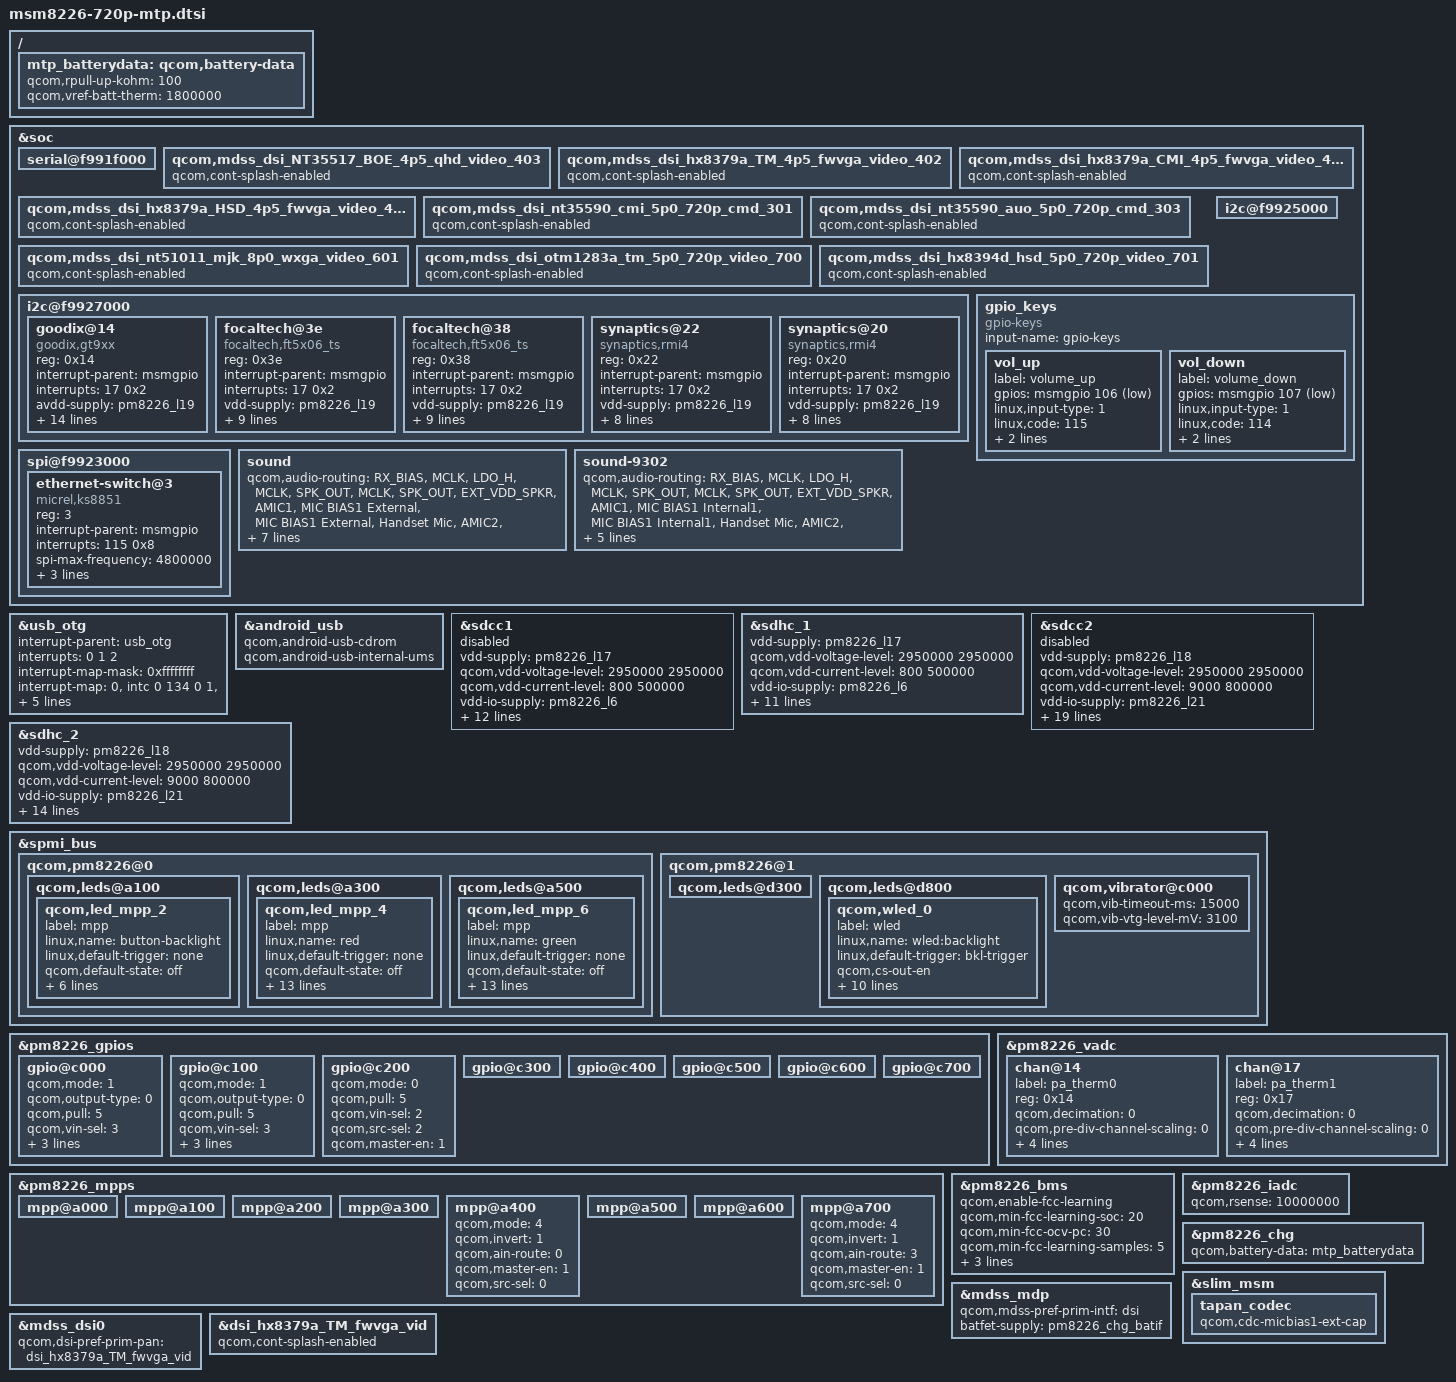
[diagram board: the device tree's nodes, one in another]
/* Copyright (c) 2013, The Linux Foundation. All rights reserved.
 *
 * This program is free software; you can redistribute it and/or modify
 * it under the terms of the GNU General Public License version 2 and
 * only version 2 as published by the Free Software Foundation.
 *
 * This program is distributed in the hope that it will be useful,
 * but WITHOUT ANY WARRANTY; without even the implied warranty of
 * MERCHANTABILITY or FITNESS FOR A PARTICULAR PURPOSE.  See the
 * GNU General Public License for more details.
 */

/include/ "msm8226-camera-sensor-mtp.dtsi"
/include/ "dsi-panel-HX8379A-CMI-IPS-4p5-FWVGA-video-zte-400.dtsi"
/include/ "dsi-panel-HX8379A-HSD-TN-4p5-FWVGA-video-zte-401.dtsi"
/include/ "dsi-panel-HX8379A-TM-TM-4p5-FWVGA-video-zte-402.dtsi"
/include/ "dsi-panel-NT35517-BOE-BOE-4p5-QHD-video-zte-403.dtsi"
/include/ "dsi-panel-nt35590-cmi-5p0-720p-cmd-zte-301.dtsi"
/include/ "dsi-panel-nt35590-auo-5p0-720p-cmd-zte-303.dtsi"
/include/ "dsi-panel-nt51011-mjk-8p0-WXGA-video-zte-601.dtsi"
/include/ "dsi-panel-otm1283a-tm-5p0-720p-video-zte-700.dtsi"
/include/ "dsi-panel-hx8394d-hsd-5p0-720p-video-zte-701.dtsi"
/include/ "dsi-panel-zte-hsd-nt35512-4p0-wvga-video.dtsi"

&soc {
	serial@f991f000 {
		status = "ok";
	};
	qcom,mdss_dsi_NT35517_BOE_4p5_qhd_video_403 {
		status = "ok";
		qcom,cont-splash-enabled;
	};
	qcom,mdss_dsi_hx8379a_TM_4p5_fwvga_video_402 {
		status = "ok";
		qcom,cont-splash-enabled;
	};

	qcom,mdss_dsi_hx8379a_CMI_4p5_fwvga_video_400 {
		status = "ok";
		qcom,cont-splash-enabled;
	};
	qcom,mdss_dsi_hx8379a_HSD_4p5_fwvga_video_401 {
		status = "ok";
		qcom,cont-splash-enabled;
	};
	qcom,mdss_dsi_nt35590_cmi_5p0_720p_cmd_301 {
		status = "ok";
		qcom,cont-splash-enabled;
	};
	qcom,mdss_dsi_nt35590_auo_5p0_720p_cmd_303 {
		status = "ok";
		qcom,cont-splash-enabled;
	};
	qcom,mdss_dsi_nt51011_mjk_8p0_wxga_video_601{
		status = "ok";
		qcom,cont-splash-enabled;
	};
	qcom,mdss_dsi_otm1283a_tm_5p0_720p_video_700{
		status = "ok";
		qcom,cont-splash-enabled;
	};
	qcom,mdss_dsi_hx8394d_hsd_5p0_720p_video_701{
		status = "ok";
		qcom,cont-splash-enabled;
	};
	i2c@f9927000 { /* BLSP1 QUP5 */
	goodix@14 {
			compatible = "goodix,gt9xx";
			reg = <0x14>;
			interrupt-parent = <&msmgpio>;
			interrupts = <17 0x2>;
            avdd-supply = <&pm8226_l19>;
			vdd-supply = <&pm8226_l19>;
			vcc_i2c-supply = <&pm8226_lvs1>;
			reset-gpios = <&msmgpio 16 0x00>;
			interrupt-gpios = <&msmgpio 17 0x00>;
			goodix,panel-coords = <0 0 480 900>;
			goodix,display-coords = <0 0 480 854>;
			goodix,button-map= <158 102 139>;
			regulator-min-microvolt = <2800000>;
			regulator-max-microvolt = <2800000>;
			goodix,family-id = <0x0>;
			goodix,no-force-update;
			goodix,i2c-pull-up;
			goodix,cfg-data = [
41 00 10 00 10 05 05 00 01 0F
28 0F 50 37 03 05 00 00 00 00
00 00 00 00 00 00 00 88 28 0A
40 42 7C 06 00 00 00 9B 03 25
00 00 00 00 00 00 64 32 00 00
00 28 6E 94 C2 02 05 00 00 04
B6 2C 00 96 36 00 7C 42 00 66
51 00 55 63 00 55 00 00 00 00
00 00 00 00 00 00 00 00 00 00
00 00 00 00 00 00 00 00 00 00
00 00 00 00 00 00 00 00 00 00
00 00 08 0A 0C 0E 10 12 14 16
18 1A 00 00 00 00 00 00 00 00
00 00 00 00 00 00 00 00 00 00
00 00 00 02 04 05 06 08 0A 0C
1D 1E 1F 20 22 24 28 29 FF 00
00 00 00 00 00 00 00 00 00 00
00 00 00 00 00 00 00 00 00 00
00 00 00 00 64 5A 50 50 50 50
46 46 5A 46 46 32 1E 00 00 00
00 00 00 00 00 00 00 00 00 00
00 00 00 00 00 00 00 00 00 00
00 00 00 00 00 00 D8 01
		];
		};
		focaltech@3e{
			compatible = "focaltech,ft5x06_ts";
			reg = <0x3e>;
			interrupt-parent = <&msmgpio>;
			interrupts = <17 0x2>;
			vdd-supply = <&pm8226_l19>;
			vcc_i2c-supply = <&pm8226_lvs1>;
			focaltech,family-id = <0x06>;
			focaltech,reset-gpio = <&msmgpio 16 0x00>;
			focaltech,irq-gpio = <&msmgpio 17 0x00>;
			focaltech,display-coords = <0 0 480 854>;
			focaltech,panel-coords = <0 0 480 854>;
			focaltech,button-map= <139 102 158>;
			focaltech,no-force-update;
			focaltech,i2c-pull-up;
		};
		focaltech@38{
			compatible = "focaltech,ft5x06_ts";
			reg = <0x38>;
			interrupt-parent = <&msmgpio>;
			interrupts = <17 0x2>;
			vdd-supply = <&pm8226_l19>;
			vcc_i2c-supply = <&pm8226_lvs1>;
			focaltech,family-id = <0x06>;
			focaltech,reset-gpio = <&msmgpio 16 0x00>;
			focaltech,irq-gpio = <&msmgpio 17 0x00>;
			focaltech,display-coords = <0 0 480 854>;
			focaltech,panel-coords = <0 0 480 854>;
			focaltech,button-map= <139 102 158>;
			focaltech,no-force-update;
			focaltech,i2c-pull-up;
		};
		synaptics@22{
			compatible = "synaptics,rmi4";
			reg = <0x22>;
			interrupt-parent = <&msmgpio>;
			interrupts = <17 0x2>;
			vdd-supply = <&pm8226_l19>;
			vcc_i2c-supply = <&pm8226_lvs1>;
			synaptics,power-down = <1>;
			synaptics,reset-gpio = <&msmgpio 16 0x00>;
			synaptics,irq-gpio = <&msmgpio 17 0x00>;
			synaptics,button-map = <158 102 139>;
			synaptics,i2c-pull-up = <1>;
			synaptics,disable-gpios = <1>;
			synaptics,fw-image-name = "fw.img";
		}; 
		synaptics@20{
			compatible = "synaptics,rmi4";
			reg = <0x20>;
			interrupt-parent = <&msmgpio>;
			interrupts = <17 0x2>;
			vdd-supply = <&pm8226_l19>;
			vcc_i2c-supply = <&pm8226_lvs1>;
			synaptics,power-down = <1>;
			synaptics,reset-gpio = <&msmgpio 16 0x00>;
			synaptics,irq-gpio = <&msmgpio 17 0x00>;
			synaptics,button-map = <158 102 139>;
			synaptics,i2c-pull-up = <1>;
			synaptics,disable-gpios = <1>;
			synaptics,fw-image-name = "fw.img";
		};
	};

	i2c@f9925000 { /* BLSP1 QUP3 */
//		nfc-nci@0e {
//			compatible = "qcom,nfc-nci";
//			reg = <0x0e>;
//			qcom,irq-gpio = <&msmgpio 21 0x00>;
//			qcom,dis-gpio = <&msmgpio 20 0x00>;
//			qcom,clk-src = "BBCLK2";
//			qcom,clk-en-gpio = <&msmgpio 0 0x00>;
//			interrupt-parent = <&msmgpio>;
//			interrupts = <21 0>;
//			qcom,clk-gpio = <&pm8226_gpios 3 0>;
//			vdd-supply = <&pm8226_l6>;
//		};
/* open following if nxp nfc is onboard */
//		nfc-nci@28{
//			compatible = "nxp,pn544";
//			reg = <0x28>;
//			nxp,ven-gpio = <&msmgpio 20 0x00>;
//			nxp,firm-gpio = <&msmgpio 22 0x00>;
//			nxp,irq-gpio = <&msmgpio 21 0x00>;
//			interrupt-parent = <&msmgpio>;
//			interrupts = <21 1>;
//			vdd-supply = <&pm8226_l6>;
//		};
	};
	gpio_keys {
		compatible = "gpio-keys";
		input-name = "gpio-keys";

        /* ZTE_MODIFY start by dingli10091962
		camera_focus {
			label = "camera_focus";
			gpios = <&msmgpio 108 0x1>;
			linux,input-type = <1>;
			linux,code = <0x210>;
			gpio-key,wakeup;
			debounce-interval = <15>;
		};

		camera_snapshot {
			label = "camera_snapshot";
			gpios = <&msmgpio 107 0x1>;
			linux,input-type = <1>;
			linux,code = <0x2fe>;
			gpio-key,wakeup;
			debounce-interval = <15>;
		};
        ZTE_MODIFY end by dingli10091962 */

		vol_up {
			label = "volume_up";
			gpios = <&msmgpio 106 0x1>;
			linux,input-type = <1>;
			linux,code = <115>;
			gpio-key,wakeup;
			debounce-interval = <15>;
		};

        // ZTE_MODIFY start by dingli10091962
		vol_down {
			label = "volume_down";
			gpios = <&msmgpio 107 0x1>;
			linux,input-type = <1>;
			linux,code = <114>;
			gpio-key,wakeup;
			debounce-interval = <15>;
		};
        // ZTE_MODIFY end by dingli10091962
	};

	spi@f9923000 {
		ethernet-switch@3 {
			compatible = "micrel,ks8851";
			reg = <3>;
			interrupt-parent = <&msmgpio>;
			interrupts = <115 0x8>;
			spi-max-frequency = <4800000>;
			rst-gpio = <&msmgpio 114 0>;
			vdd-io-supply = <&pm8226_lvs1>;
			vdd-phy-supply = <&pm8226_lvs1>;
		};
	};

	sound {
		qcom,audio-routing =
			"RX_BIAS", "MCLK",
			"LDO_H", "MCLK",
			"SPK_OUT", "MCLK",
			"SPK_OUT", "EXT_VDD_SPKR",
			"AMIC1", "MIC BIAS1 External",
			"MIC BIAS1 External", "Handset Mic",
			"AMIC2", "MIC BIAS2 External",
			"MIC BIAS2 External", "Headset Mic",
			"AMIC4", "MIC BIAS2 External",
			"MIC BIAS2 External", "ANCRight Headset Mic",
			"AMIC5", "MIC BIAS2 External",
			"MIC BIAS2 External", "ANCLeft Headset Mic";

		qcom,cdc-mclk-gpios = <&pm8226_gpios 1 0>;
		qcom,cdc-vdd-spkr-gpios = <&pm8226_gpios 2 0>;
	};

	sound-9302 {
		qcom,audio-routing =
			"RX_BIAS", "MCLK",
			"LDO_H", "MCLK",
			"SPK_OUT", "MCLK",
			"SPK_OUT", "EXT_VDD_SPKR",
			"AMIC1", "MIC BIAS1 Internal1",
			"MIC BIAS1 Internal1", "Handset Mic",
			"AMIC2", "MIC BIAS2 External",
			"MIC BIAS2 External", "Headset Mic",
			"AMIC3", "MIC BIAS1 External",
			"MIC BIAS1 External", "Handset Mic";

		qcom,cdc-mclk-gpios = <&pm8226_gpios 1 0>;
		qcom,cdc-vdd-spkr-gpios = <&pm8226_gpios 2 0>;
	};
};

&usb_otg {
	#address-cells = <0>;
	interrupt-parent = <&usb_otg>;
	interrupts = <0 1 2>;
	#interrupt-cells = <1>;
	interrupt-map-mask = <0xffffffff>;
	interrupt-map = <0 &intc 0 134 0
			1 &intc 0 140 0
			2 &spmi_bus 0x0 0x0 0x9 0x0>;
	interrupt-names = "core_irq", "async_irq", "pmic_id_irq";

	qcom,hsusb-otg-mode = <3>;
//zz
        zte,seq-override = <0x44 0x80 0x6d 0x81 0x34 0x82 0x13 0x83 0xffffffff>;
//zz
	vbus_otg-supply = <&pm8226_chg_otg>;
};
//zz
&android_usb {
	qcom,android-usb-cdrom;
	qcom,android-usb-internal-ums;
};
//zz
&sdcc1 {
	vdd-supply = <&pm8226_l17>;
	qcom,vdd-voltage-level = <2950000 2950000>;
	qcom,vdd-current-level = <800 500000>;

	vdd-io-supply = <&pm8226_l6>;
	qcom,vdd-io-always-on;
	qcom,vdd-io-voltage-level = <1800000 1800000>;
	qcom,vdd-io-current-level = <250 154000>;

	qcom,pad-pull-on = <0x0 0x3 0x3>; /* no-pull, pull-up, pull-up */
	qcom,pad-pull-off = <0x0 0x3 0x3>; /* no-pull, pull-up, pull-up */
	qcom,pad-drv-on = <0x4 0x4 0x4>; /* 10mA, 10mA, 10mA */
	qcom,pad-drv-off = <0x0 0x0 0x0>; /* 2mA, 2mA, 2mA */

	qcom,clk-rates = <400000 25000000 50000000 100000000 200000000>;
	qcom,sup-voltages = <2950 2950>;

	qcom,bus-speed-mode = "HS200_1p8v", "DDR_1p8v";
	qcom,nonremovable;

	status = "disabled";
};

&sdhc_1 {
	vdd-supply = <&pm8226_l17>;
	qcom,vdd-voltage-level = <2950000 2950000>;
	qcom,vdd-current-level = <800 500000>;

	vdd-io-supply = <&pm8226_l6>;
	qcom,vdd-io-always-on;
	qcom,vdd-io-voltage-level = <1800000 1800000>;
	qcom,vdd-io-current-level = <250 154000>;

	qcom,pad-pull-on = <0x0 0x3 0x3>; /* no-pull, pull-up, pull-up */
	qcom,pad-pull-off = <0x0 0x3 0x3>; /* no-pull, pull-up, pull-up */
	qcom,pad-drv-on = <0x4 0x4 0x4>; /* 10mA, 10mA, 10mA */
	qcom,pad-drv-off = <0x0 0x0 0x0>; /* 2mA, 2mA, 2mA */

	qcom,clk-rates = <400000 25000000 50000000 100000000 200000000>;
	qcom,bus-speed-mode = "HS200_1p8v", "DDR_1p8v";
	qcom,nonremovable;

	status = "ok";
};

&sdcc2 {
	vdd-supply = <&pm8226_l18>;
	qcom,vdd-voltage-level = <2950000 2950000>;
	qcom,vdd-current-level = <9000 800000>;

	vdd-io-supply = <&pm8226_l21>;
	qcom,vdd-io-voltage-level = <1800000 2950000>;
	qcom,vdd-io-current-level = <6 22000>;

	qcom,pad-pull-on = <0x0 0x3 0x3>; /* no-pull, pull-up, pull-up */
	qcom,pad-pull-off = <0x0 0x3 0x3>; /* no-pull, pull-up, pull-up */
	qcom,pad-drv-on = <0x4 0x4 0x4>; /* 10mA, 10mA, 10mA */
	qcom,pad-drv-off = <0x0 0x0 0x0>; /* 2mA, 2mA, 2mA */

	qcom,clk-rates = <400000 25000000 50000000 100000000 200000000>;
	qcom,sup-voltages = <2950 2950>;

	qcom,xpc;
	qcom,bus-speed-mode = "SDR12", "SDR25", "SDR50", "DDR50", "SDR104";
	qcom,current-limit = <600>; #address-cells = <0>; interrupt-parent = <&sdcc2>;
	interrupts = <0 1 2>;
	#interrupt-cells = <1>;
	interrupt-map-mask = <0xffffffff>;
	interrupt-map = <0 &intc 0 125 0
			1 &intc 0 220 0
			2 &msmgpio 38 0x3>;
	interrupt-names = "core_irq", "bam_irq", "status_irq";
	cd-gpios = <&msmgpio 38 0x1>;

	status = "disabled";
};

&sdhc_2 {
	vdd-supply = <&pm8226_l18>;
	qcom,vdd-voltage-level = <2950000 2950000>;
	qcom,vdd-current-level = <9000 800000>;

	vdd-io-supply = <&pm8226_l21>;
	qcom,vdd-io-voltage-level = <1800000 2950000>;
	qcom,vdd-io-current-level = <6 22000>;

	qcom,pad-pull-on = <0x0 0x3 0x3>; /* no-pull, pull-up, pull-up */
	qcom,pad-pull-off = <0x0 0x3 0x3>; /* no-pull, pull-up, pull-up */
	qcom,pad-drv-on = <0x4 0x4 0x4>; /* 10mA, 10mA, 10mA */
	qcom,pad-drv-off = <0x0 0x0 0x0>; /* 2mA, 2mA, 2mA */

	qcom,clk-rates = <400000 25000000 50000000 100000000 200000000>;

	#address-cells = <0>;
	interrupt-parent = <&sdhc_2>;
	interrupts = <0 1 2>;
	#interrupt-cells = <1>;
	interrupt-map-mask = <0xffffffff>;
	interrupt-map = <0 &intc 0 125 0
			1 &intc 0 221 0
			2 &msmgpio 38 0x3>;
	interrupt-names = "hc_irq", "pwr_irq", "status_irq";
	cd-gpios = <&msmgpio 38 0x1>;

	status = "ok";
};

&spmi_bus {
	qcom,pm8226@0 {
		qcom,leds@a100 {
			status = "okay";
			qcom,led_mpp_2 {
				label = "mpp";
				linux,name = "button-backlight";
				linux,default-trigger = "none";
				qcom,default-state = "off";
				qcom,max-current = <40>;
				qcom,current-setting = <5>;
				qcom,id = <6>;
				qcom,mode = "manual";
				qcom,source-sel = <1>;
				qcom,mode-ctrl = <0x60>;
			};
		};

		qcom,leds@a300 {
			status = "okay";
			qcom,led_mpp_4 {
				label = "mpp";
				linux,name = "red";
				linux,default-trigger = "none";
				qcom,default-state = "off";
				qcom,max-current = <40>;
				qcom,current-setting = <5>;
				qcom,id = <6>;
				qcom,mode = "pwm";
				qcom,pwm-us = <1000>;
				qcom,source-sel = <8>;
				qcom,mode-ctrl = <0x60>;
				qcom,pwm-channel = <0>;
				qcom,start-idx = <1>;
				qcom,ramp-step-ms = <120>;
				qcom,duty-pcts = [00 00 00 00 00
						  00 00 00 00 00
						  50 00 00 00 00
						  00 00 00 00 00
						  00];
				qcom,use-blink;
			};
		};

		qcom,leds@a500 {
			status = "okay";
			qcom,led_mpp_6 {
				label = "mpp";
				linux,name = "green";
				linux,default-trigger = "none";
				qcom,default-state = "off";
				qcom,max-current = <40>;
				qcom,current-setting = <5>;
				qcom,id = <6>;
				qcom,mode = "pwm";
				qcom,pwm-us = <1000>;
				qcom,mode-ctrl = <0x60>;
				qcom,source-sel = <10>;
				qcom,pwm-channel = <5>;
				qcom,start-idx = <1>;
				qcom,ramp-step-ms = <120>;
				qcom,duty-pcts = [00 00 00 00 00
						  00 00 00 00 00
						  50 00 00 00 00
						  00 00 00 00 00
						  00];
				qcom,use-blink;
			};
		};
	};

	qcom,pm8226@1 {
                qcom,leds@d300 {
                        status = "okay";
                };

		qcom,leds@d800 {
			status = "okay";
			qcom,wled_0 {
				label = "wled";
				linux,name = "wled:backlight";
				linux,default-trigger = "bkl-trigger";
				qcom,cs-out-en;
				qcom,op-fdbck = <1>;
				qcom,default-state = "on";
				qcom,max-current = <20>;
				qcom,ctrl-delay-us = <0>;
				qcom,boost-curr-lim = <3>;
				qcom,cp-sel = <0>;
				qcom,switch-freq = <11>;
				qcom,ovp-val = <0>;
				qcom,num-strings = <1>;
				qcom,id = <0>;
			};
		};

		qcom,vibrator@c000 {
			status = "okay";
			qcom,vib-timeout-ms = <15000>;
			qcom,vib-vtg-level-mV = <3100>;
		};
	};
};

&pm8226_gpios {
	gpio@c000 { /* GPIO 1 */
		/* XO_PMIC_CDC_MCLK enable for tapan codec */
		qcom,mode = <1>;		/* Digital output */
		qcom,output-type = <0>;	/* CMOS logic */
		qcom,pull = <5>;		/* QPNP_PIN_PULL_NO*/
		qcom,vin-sel = <3>;		/* QPNP_PIN_VIN3 */
		qcom,out-strength = <3>;/* QPNP_PIN_OUT_STRENGTH_HIGH */
		qcom,src-sel = <2>;		/* QPNP_PIN_SEL_FUNC_1 */
		qcom,master-en = <1>;	/* Enable GPIO */
	};

	gpio@c100 { /* GPIO 2 */
		qcom,mode = <1>;
		qcom,output-type = <0>;
		qcom,pull = <5>;
		qcom,vin-sel = <3>;
		qcom,out-strength = <3>;
		qcom,src-sel = <2>;
		qcom,master-en = <1>;
	};

	gpio@c200 { /* GPIO 3 */
		qcom,mode = <0>;		/* QPNP_PIN_MODE_DIG_IN */
		qcom,pull = <5>;		/* QPNP_PIN_PULL_NO */
		qcom,vin-sel = <2>;		/* QPNP_PIN_VIN2 */
		qcom,src-sel = <2>;		/* QPNP_PIN_SEL_FUNC_1 */
		qcom,master-en = <1>;
	};

	gpio@c300 { /* GPIO 4 */
	};

	gpio@c400 { /* GPIO 5 */
	};

	gpio@c500 { /* GPIO 6 */
	};

	gpio@c600 { /* GPIO 7 */
	};

	gpio@c700 { /* GPIO 8 */
	};
};

&pm8226_mpps {
	mpp@a000 { /* MPP 1 */
	};

	mpp@a100 { /* MPP 2 */
	};

	mpp@a200 { /* MPP 3 */
	};

	mpp@a300 { /* MPP 4 */
	};

	mpp@a400 { /* MPP 5 */
		/* PA_THERM0 config */
		qcom,mode = <4>; /* AIN input */
		qcom,invert = <1>; /* Enable MPP */
		qcom,ain-route = <0>; /* AMUX 5 */
		qcom,master-en = <1>;
		qcom,src-sel = <0>; /* Function constant */
	};

	mpp@a500 { /* MPP 6 */
	};

	mpp@a600 { /* MPP 7 */
	};

	mpp@a700 { /* MPP 8 */
		/* PA_THERM1 config */
		qcom,mode = <4>; /* AIN input */
		qcom,invert = <1>; /* Enable MPP */
		qcom,ain-route = <3>; /* AMUX 8 */
		qcom,master-en = <1>;
		qcom,src-sel = <0>; /* Function constant */
	};
};

&pm8226_vadc {
	chan@14 {
		label = "pa_therm0";
		reg = <0x14>;
		qcom,decimation = <0>;
		qcom,pre-div-channel-scaling = <0>;
		qcom,calibration-type = "ratiometric";
		qcom,scale-function = <2>;
		qcom,hw-settle-time = <2>;
		qcom,fast-avg-setup = <0>;
	};

	chan@17 {
		label = "pa_therm1";
		reg = <0x17>;
		qcom,decimation = <0>;
		qcom,pre-div-channel-scaling = <0>;
		qcom,calibration-type = "ratiometric";
		qcom,scale-function = <2>;
		qcom,hw-settle-time = <2>;
		qcom,fast-avg-setup = <0>;
	};
};

/ {
	mtp_batterydata: qcom,battery-data {
		qcom,rpull-up-kohm = <100>;
		qcom,vref-batt-therm = <1800000>;

		/include/ "batterydata-zte-4v35-2000mah.dtsi"
		/include/ "batterydata-zte-4v35-2300mah.dtsi"
		/include/ "batterydata-zte-rd-gy-4v35-2300mah.dtsi"
		/include/ "batterydata-zte-4v2-4000mah.dtsi"
	};
};

&pm8226_bms {
	status = "ok";
	qcom,enable-fcc-learning;
	qcom,min-fcc-learning-soc = <20>;
	qcom,min-fcc-ocv-pc = <30>;
	qcom,min-fcc-learning-samples = <5>;
	qcom,fcc-resolution = <10>;
	qcom,battery-data = <&mtp_batterydata>;
	qcom,use-external-rsense;
};

&pm8226_iadc {
	qcom,rsense = <10000000>;
};

&pm8226_chg {
	qcom,battery-data = <&mtp_batterydata>;
};

&slim_msm {
	tapan_codec {
		qcom,cdc-micbias1-ext-cap;
	};
};

&mdss_mdp {
	qcom,mdss-pref-prim-intf = "dsi";
	batfet-supply = <&pm8226_chg_batif>;
};

&mdss_dsi0 {
	qcom,dsi-pref-prim-pan = <&dsi_hx8379a_TM_fwvga_vid>;
};

&dsi_hx8379a_TM_fwvga_vid {
	qcom,cont-splash-enabled;
};
